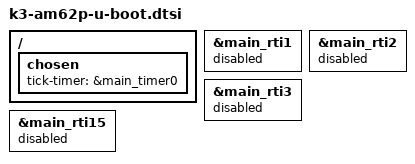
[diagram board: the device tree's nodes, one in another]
// SPDX-License-Identifier: GPL-2.0
/*
 * Common AM62P U-Boot dts file
 * Copyright (C) 2022-2025 Texas Instruments Incorporated - https://www.ti.com/
 */

/ {
	chosen {
		tick-timer = &main_timer0;
	};
};

&main_rti1 {
	status = "disabled";
};

&main_rti2 {
	status = "disabled";
};

&main_rti3 {
	status = "disabled";
};

&main_rti15 {
	status = "disabled";
};
